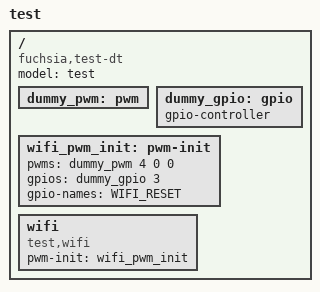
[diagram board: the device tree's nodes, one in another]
// Copyright 2024 The Fuchsia Authors. All rights reserved.
// Use of this source code is governed by a BSD-style license that can be
// found in the LICENSE file.
/dts-v1/;

/ {
	compatible = "fuchsia,test-dt";
	model = "test";
	#address-cells = <2>;
	#size-cells = <2>;

	dummy_pwm: pwm {
		#pwm-cells = <3>;
	};

	dummy_gpio: gpio {
		gpio-controller;
		#gpio-cells = <2>;
	};

	wifi_pwm_init: pwm-init {
		pwms = <&dummy_pwm 4 0 0>;
		gpios = <&dummy_gpio 3 0>;
		gpio-names = "WIFI_RESET";
	};

	wifi {
		compatible = "test,wifi";
		pwm-init = <&wifi_pwm_init>;
	};
};
